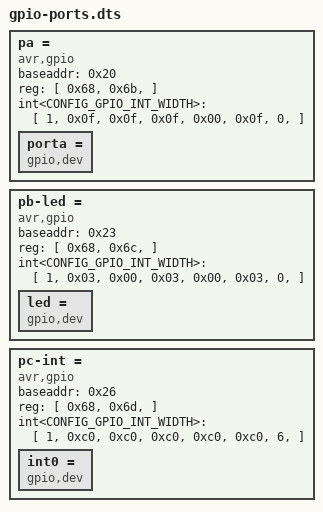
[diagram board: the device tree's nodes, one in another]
/**
 * Copyright (C) 2022 Jan Nowotsch
 * Author Jan Nowotsch	<jan.nowotsch@gmail.com>
 *
 * Released under the terms of the GNU GPL v2.0
 */



#include <config/config.h>


pa = {
	compatible = "avr,gpio";

	/* gpio hardware (dt_data_t) */
	baseaddr = 0x20;	// porta

	reg = [
		0x68,			// PCICR
		0x6b,			// PCMSK0
	];

	/* gpio config gpio_cfg_t) */
	int<CONFIG_GPIO_INT_WIDTH> = [
		1,				// mode (normal)
		0x0f,			// pin mask
		0x0f,			// in mask
		0x0f,			// out mask
		0x00,			// int mask
		0x0f,			// invert mask (inverted)
		0,				// interrupt
	];

	porta = {
		compatible = "gpio,dev";
	};
};

pb-led = {
	compatible = "avr,gpio";

	/* gpio hardware (dt_data_t) */
	baseaddr = 0x23;	// portb

	reg = [
		0x68,			// PCICR
		0x6c,			// PCMSK1
	];

	/* gpio config gpio_cfg_t) */
	int<CONFIG_GPIO_INT_WIDTH> = [
		1,				// mode (normal)
		0x03,			// pin mask
		0x00,			// in mask
		0x03,			// out mask
		0x00,			// int mask
		0x03,			// invert mask (inverted)
		0,				// interrupt
	];

	led = {
		compatible = "gpio,dev";
	};
};

pc-int = {
	compatible = "avr,gpio";

	/* gpio hardware (dt_data_t) */
	baseaddr = 0x26;	// portc

	reg = [
		0x68,			// PCICR
		0x6d,			// PCMSK2
	];

	/* gpio config gpio_cfg_t) */
	int<CONFIG_GPIO_INT_WIDTH> = [
		1,				// mode (normal)
		0xc0,			// pin mask
		0xc0,			// in mask
		0xc0,			// out mask
		0xc0,			// int mask
		0xc0,			// invert mask (inverted)
		6,				// interrupt (pcint2)
	];

	int0 = {
		compatible = "gpio,dev";
	};
};
